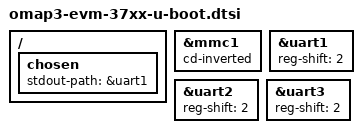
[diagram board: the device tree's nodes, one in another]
/*
 * U-Boot additions
 *
 * (C) Copyright 2017 Derald D. Woods <woods.technical@gmail.com>
 *
 * SPDX-License-Identifier:	GPL-2.0+
 */

/ {
	chosen {
		stdout-path = &uart1;
	};
};

&mmc1 {
	cd-inverted;
};

&uart1 {
	reg-shift = <2>;
};

&uart2 {
	reg-shift = <2>;
};

&uart3 {
	reg-shift = <2>;
};
